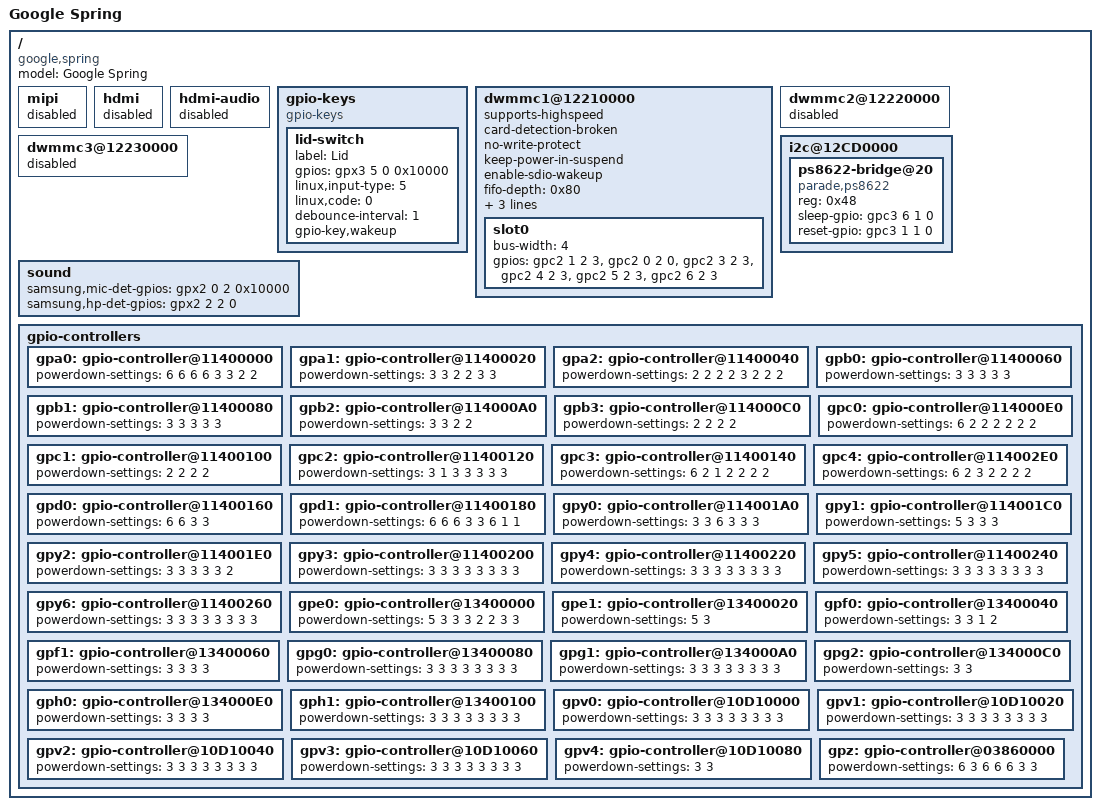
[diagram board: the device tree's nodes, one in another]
/*
 * Google Spring board device tree source
 *
 * Copyright (c) 2012 Google, Inc
 *
 * This program is free software; you can redistribute it and/or modify
 * it under the terms of the GNU General Public License version 2 as
 * published by the Free Software Foundation.
*/

/dts-v1/;
/include/ "exynos5250.dtsi"
/include/ "cros5250-common.dtsi"

/ {
	model = "Google Spring";
	compatible = "google,spring", "samsung,exynos5250";

	mipi {
		status = "disabled";
	};

	hdmi {
		status = "disabled";
	};

	hdmi-audio {
		status = "disabled";
	};

	gpio-keys {
		compatible = "gpio-keys";

		lid-switch {
			label = "Lid";
			gpios = <&gpx3 5 0 0x10000 0>;
			linux,input-type = <5>; /* EV_SW */
			linux,code = <0>; /* SW_LID */
			debounce-interval = <1>;
			gpio-key,wakeup;
		};
	};

	dwmmc1@12210000 {
		/*
		 * MMC1 port is used for external Wifi card SDIO connection.
		 *
		 * We override the default configuration for this port which
		 * disables it in cros5250-common.dtsi.
		 */
		status = "okay";
		supports-highspeed;
		card-detection-broken;
		no-write-protect;
		keep-power-in-suspend;
		enable-sdio-wakeup;
		fifo-depth = <0x80>;
		card-detect-delay = <200>;
		samsung,dw-mshc-sdr-timing = <2 3 3>;
		samsung,dw-mshc-ddr-timing = <1 2 3>;

		slot0 {
			bus-width = <4>;
			gpios = <&gpc2 1 2 3 3>, <&gpc2 0 2 0 3>,
				<&gpc2 3 2 3 3>, <&gpc2 4 2 3 3>,
				<&gpc2 5 2 3 3>, <&gpc2 6 2 3 3>;
		};
	};

	dwmmc2@12220000 {
		/* MMC2 pins are used as GPIO for eDP bridge control */
		status = "disabled";
	};

	dwmmc3@12230000 {
		/*
		 * Nothing is connected on MMC3 port : disable it.
		 *
		 * We override the default configuration for this port which
		 * configures it for SDIO in cros5250-common.dtsi.
		 */
		status = "disabled";
	};

	i2c@12CD0000 {
		ps8622-bridge@20 {
			compatible = "parade,ps8622";
			reg = <0x48>;
			sleep-gpio = <&gpc3 6 1 0 0>;
			reset-gpio = <&gpc3 1 1 0 0>;
		};
	};

	sound {
		samsung,mic-det-gpios = <&gpx2 0 2 0x10000 0>;
		samsung,hp-det-gpios = <&gpx2 2 2 0 0>;
	};

	gpio-controllers {
		gpa0: gpio-controller@11400000 {
			powerdown-settings = <6 6 6 6 3 3 2 2>;
		};

		gpa1: gpio-controller@11400020 {
			powerdown-settings = <3 3 2 2 3 3>;
		};

		gpa2: gpio-controller@11400040 {
			powerdown-settings = <2 2 2 2 3 2 2 2>;
		};

		gpb0: gpio-controller@11400060 {
			powerdown-settings = <3 3 3 3 3>;
		};

		gpb1: gpio-controller@11400080 {
			powerdown-settings = <3 3 3 3 3>;
		};

		gpb2: gpio-controller@114000A0 {
			powerdown-settings = <3 3 2 2>;
		};

		gpb3: gpio-controller@114000C0 {
			powerdown-settings = <2 2 2 2>;
		};

		gpc0: gpio-controller@114000E0 {
			powerdown-settings = <6 2 2 2 2 2 2>;
		};

		gpc1: gpio-controller@11400100 {
			powerdown-settings = <2 2 2 2>;
		};

		gpc2: gpio-controller@11400120 {
			powerdown-settings = <3 1 3 3 3 3 3>;
		};

		gpc3: gpio-controller@11400140 {
			powerdown-settings = <6 2 1 2 2 2 2>;
		};

		gpc4: gpio-controller@114002E0 {
			powerdown-settings = <6 2 3 2 2 2 2>;
		};

		gpd0: gpio-controller@11400160 {
			powerdown-settings = <6 6 3 3>;
		};

		gpd1: gpio-controller@11400180 {
			powerdown-settings = <6 6 6 3 3 6 1 1>;
		};

		gpy0: gpio-controller@114001A0 {
			powerdown-settings = <3 3 6 3 3 3>;
		};

		gpy1: gpio-controller@114001C0 {
			powerdown-settings = <5 3 3 3>;
		};

		gpy2: gpio-controller@114001E0 {
			powerdown-settings = <3 3 3 3 3 2>;
		};

		gpy3: gpio-controller@11400200 {
			powerdown-settings = <3 3 3 3 3 3 3 3>;
		};

		gpy4: gpio-controller@11400220 {
			powerdown-settings = <3 3 3 3 3 3 3 3>;
		};

		gpy5: gpio-controller@11400240 {
			powerdown-settings = <3 3 3 3 3 3 3 3>;
		};

		gpy6: gpio-controller@11400260 {
			powerdown-settings = <3 3 3 3 3 3 3 3>;
		};

		/* gpx0: No powerdown mode, uses active mode on suspend */
		/* gpx1: No powerdown mode, uses active mode on suspend */
		/* gpx2: No powerdown mode, uses active mode on suspend */
		/* gpx3: No powerdown mode, uses active mode on suspend */

		gpe0: gpio-controller@13400000 {
			powerdown-settings = <5 3 3 3 2 2 3 3>;
		};

		gpe1: gpio-controller@13400020 {
			powerdown-settings = <5 3>;
		};

		gpf0: gpio-controller@13400040 {
			powerdown-settings = <3 3 1 2>;
		};

		gpf1: gpio-controller@13400060 {
			powerdown-settings = <3 3 3 3>;
		};

		gpg0: gpio-controller@13400080 {
			powerdown-settings = <3 3 3 3 3 3 3 3>;
		};

		gpg1: gpio-controller@134000A0 {
			powerdown-settings = <3 3 3 3 3 3 3 3>;
		};

		gpg2: gpio-controller@134000C0 {
			powerdown-settings = <3 3>;
		};

		gph0: gpio-controller@134000E0 {
			powerdown-settings = <3 3 3 3>;
		};

		gph1: gpio-controller@13400100 {
			powerdown-settings = <3 3 3 3 3 3 3 3>;
		};

		gpv0: gpio-controller@10D10000 {
			powerdown-settings = <3 3 3 3 3 3 3 3>;
		};

		gpv1: gpio-controller@10D10020 {
			powerdown-settings = <3 3 3 3 3 3 3 3>;
		};

		gpv2: gpio-controller@10D10040 {
			powerdown-settings = <3 3 3 3 3 3 3 3>;
		};

		gpv3: gpio-controller@10D10060 {
			powerdown-settings = <3 3 3 3 3 3 3 3>;
		};

		gpv4: gpio-controller@10D10080 {
			powerdown-settings = <3 3>;
		};

		gpz: gpio-controller@03860000 {
			powerdown-settings = <6 3 6 6 6 3 3>;
		};
	};

};
